AUTOSAR XML (schema 4-3-0)
standard types defined: boolean, float64, uint16, uint8, boolean_CompuMethod, boolean_DataConstr, float64_DataConstr, uint16_DataConstr, uint8_DataConstr
package /ComponentTypes
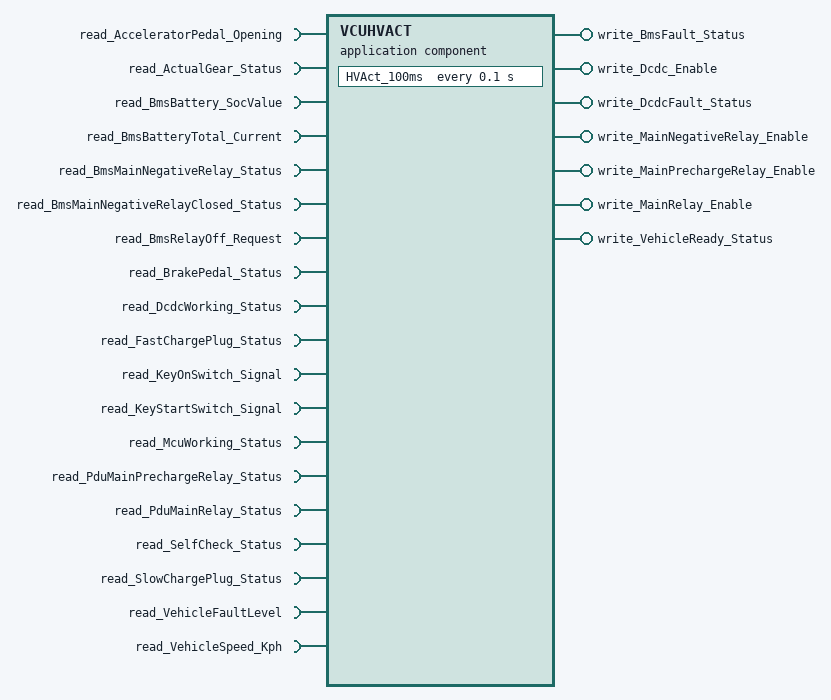
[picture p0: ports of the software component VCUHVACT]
  application sw component type VCUHVACT
    7 x provide port:
      write_BmsFault_Status: nonqueued-sender-com-spec{data-element=write_BmsFault_Status/unit8_t, init-value=0}, provided-interface=write_BmsFault_Status
      write_Dcdc_Enable: nonqueued-sender-com-spec{data-element=write_Dcdc_Enable/uint8_t, init-value=0}, provided-interface=write_Dcdc_Enable
      write_DcdcFault_Status: nonqueued-sender-com-spec{data-element=write_DcdcFault_Status/uint8_t, init-value=0}, provided-interface=write_DcdcFault_Status
      write_MainNegativeRelay_Enable: nonqueued-sender-com-spec{data-element=write_MainNegativeRelay_Enable/unit8_t, init-value=0}, provided-interface=write_MainNegativeRelay_Enable
      write_MainPrechargeRelay_Enable: nonqueued-sender-com-spec{data-element=write_MainPrechargeRelay_Enable/uint8_t, init-value=0}, provided-interface=write_MainPrechargeRelay_Enable
      write_MainRelay_Enable: nonqueued-sender-com-spec{data-element=write_MainRelay_Enable/uint8_t, init-value=0}, provided-interface=write_MainRelay_Enable
      write_VehicleReady_Status: nonqueued-sender-com-spec{data-element=write_VehicleReady_Status/uint8_t, init-value=0}, provided-interface=write_VehicleReady_Status
    19 x require port:
      read_AcceleratorPedal_Opening: nonqueued-receiver-com-spec{data-element=uint16_t, filter=data-filter-type=ALWAYS, init-value=0}, required-interface=read_AcceleratorPedal_Opening
      read_ActualGear_Status: nonqueued-receiver-com-spec{data-element=read_ActualGear_Status/uint8_t, filter=data-filter-type=ALWAYS, init-value=0}, required-interface=read_ActualGear_Status
      read_BmsBattery_SocValue: nonqueued-receiver-com-spec{data-element=read_BmsBattery_SocValue/float64, filter=data-filter-type=ALWAYS, init-value=0}, required-interface=read_BmsBattery_SocValue
      read_BmsBatteryTotal_Current: nonqueued-receiver-com-spec{data-element=read_BmsBatteryTotal_Current/float64, filter=data-filter-type=ALWAYS, init-value=0}, required-interface=read_BmsBatteryTotal_Current
      read_BmsMainNegativeRelay_Status: nonqueued-receiver-com-spec{data-element=read_BmsMainNegativeRelay_Status/bool, filter=data-filter-type=ALWAYS, init-value=0}, required-interface=read_BmsMainNegativeRelay_Status
      read_BmsMainNegativeRelayClosed_Status: nonqueued-receiver-com-spec{data-element=read_BmsMainNegativeRelayClosed_Status/uint8_t, filter=data-filter-type=ALWAYS, init-value=0}, required-interface=read_BmsMainNegativeRelayClosed_Status
      read_BmsRelayOff_Request: nonqueued-receiver-com-spec{data-element=read_BmsRelayOff_Request/uint8_t, filter=data-filter-type=ALWAYS, init-value=0}, required-interface=read_BmsRelayOff_Request
      read_BrakePedal_Status: nonqueued-receiver-com-spec{data-element=read_BrakePedal_Status/uint8_t, filter=data-filter-type=ALWAYS, init-value=0}, required-interface=read_BrakePedal_Status
      read_DcdcWorking_Status: nonqueued-receiver-com-spec{data-element=read_DcdcWorking_Status/uint8_t, filter=data-filter-type=ALWAYS, init-value=0}, required-interface=read_DcdcWorking_Status
      read_FastChargePlug_Status: nonqueued-receiver-com-spec{data-element=read_FastChargePlug_Status/bool, filter=data-filter-type=ALWAYS, init-value=0}, required-interface=read_FastChargePlug_Status
      read_KeyOnSwitch_Signal: nonqueued-receiver-com-spec{data-element=read_KeyOnSwitch_Signal/bool, filter=data-filter-type=ALWAYS, init-value=0}, required-interface=read_KeyOnSwitch_Signal
      read_KeyStartSwitch_Signal: nonqueued-receiver-com-spec{data-element=read_KeyStartSwitch_Signal/bool, filter=data-filter-type=ALWAYS, init-value=0}, required-interface=read_KeyStartSwitch_Signal
      read_McuWorking_Status: nonqueued-receiver-com-spec{data-element=read_McuWorking_Status/uint8_t, filter=data-filter-type=ALWAYS, init-value=0}, required-interface=read_McuWorking_Status
      read_PduMainPrechargeRelay_Status: nonqueued-receiver-com-spec{data-element=read_PduMainPrechargeRelay_Status/uint8_t, filter=data-filter-type=ALWAYS, init-value=0}, required-interface=read_PduMainPrechargeRelay_Status
      read_PduMainRelay_Status: nonqueued-receiver-com-spec{data-element=read_PduMainRelay_Status/uint8_t, filter=data-filter-type=ALWAYS, init-value=0}, required-interface=read_PduMainRelay_Status
      read_SelfCheck_Status: nonqueued-receiver-com-spec{data-element=read_SelfCheck_Status/bool, filter=data-filter-type=ALWAYS, init-value=0}, required-interface=read_SelfCheck_Status
      read_SlowChargePlug_Status: nonqueued-receiver-com-spec{data-element=read_SlowChargePlug_Status/bool, filter=data-filter-type=ALWAYS, init-value=0}, required-interface=read_SlowChargePlug_Status
      read_VehicleFaultLevel: nonqueued-receiver-com-spec{data-element=read_VehicleFaultLevel/uint8_t, filter=data-filter-type=ALWAYS, init-value=0}, required-interface=read_VehicleFaultLevel
      read_VehicleSpeed_Kph: nonqueued-receiver-com-spec{data-element=read_VehicleSpeed_Kph/float64, filter=data-filter-type=ALWAYS, init-value=0}, required-interface=read_VehicleSpeed_Kph
    behavior VCUHVACT_InternalBehavior
      timing event TMT_HVAct_100ms: start-on-event=HVAct_100ms, period=0.1
      runnable HVAct_100ms: minimum-start-interval=0.1
        data-receive-point-by-arguments:
          19 x access:
            REC_read_AcceleratorPedal_Opening_uint16_t: accessed-variable=read_AcceleratorPedal_Opening.uint16_t
            REC_read_ActualGear_Status_uint8_t: accessed-variable=read_ActualGear_Status.uint8_t
            REC_read_BmsBattery_SocValue_float64: accessed-variable=read_BmsBattery_SocValue.float64
            REC_read_BmsBatteryTotal_Current_float64: accessed-variable=read_BmsBatteryTotal_Current.float64
            REC_read_BmsMainNegativeRelay_Status_bool: accessed-variable=read_BmsMainNegativeRelay_Status.bool
            REC_read_BmsMainNegativeRelayClosed_Status_uint8_t: accessed-variable=read_BmsMainNegativeRelayClosed_Status.uint8_t
            REC_read_BmsRelayOff_Request_uint8_t: accessed-variable=read_BmsRelayOff_Request.uint8_t
            REC_read_BrakePedal_Status_uint8_t: accessed-variable=read_BrakePedal_Status.uint8_t
            REC_read_DcdcWorking_Status_uint8_t: accessed-variable=read_DcdcWorking_Status.uint8_t
            REC_read_FastChargePlug_Status_bool: accessed-variable=read_FastChargePlug_Status.bool
            REC_read_KeyOnSwitch_Signal_bool: accessed-variable=read_KeyOnSwitch_Signal.bool
            REC_read_KeyStartSwitch_Signal_bool: accessed-variable=read_KeyStartSwitch_Signal.bool
            REC_read_McuWorking_Status_uint8_t: accessed-variable=read_McuWorking_Status.uint8_t
            REC_read_PduMainPrechargeRelay_Status_uint8_t: accessed-variable=read_PduMainPrechargeRelay_Status.uint8_t
            REC_read_PduMainRelay_Status_uint8_t: accessed-variable=read_PduMainRelay_Status.uint8_t
            REC_read_SelfCheck_Status_bool: accessed-variable=read_SelfCheck_Status.bool
            REC_read_SlowChargePlug_Status_bool: accessed-variable=read_SlowChargePlug_Status.bool
            REC_read_VehicleFaultLevel_uint8_t: accessed-variable=read_VehicleFaultLevel.uint8_t
            REC_read_VehicleSpeed_Kph_float64: accessed-variable=read_VehicleSpeed_Kph.float64
        data-send-points:
          7 x access:
            SEND_write_BmsFault_Status_unit8_t: accessed-variable=write_BmsFault_Status.unit8_t
            SEND_write_Dcdc_Enable_uint8_t: accessed-variable=write_Dcdc_Enable.uint8_t
            SEND_write_DcdcFault_Status_uint8_t: accessed-variable=write_DcdcFault_Status.uint8_t
            SEND_write_MainNegativeRelay_Enable_unit8_t: accessed-variable=write_MainNegativeRelay_Enable.unit8_t
            SEND_write_MainPrechargeRelay_Enable_uint8_t: accessed-variable=write_MainPrechargeRelay_Enable.uint8_t
            SEND_write_MainRelay_Enable_uint8_t: accessed-variable=write_MainRelay_Enable.uint8_t
            SEND_write_VehicleReady_Status_uint8_t: accessed-variable=write_VehicleReady_Status.uint8_t
  swc implementation VCUHVACT_Implementation: behavior=VCUHVACT_InternalBehavior
    code-descriptors:
      code Default: artifact-descriptors=autosar-engineering-object={short-label=Default, category=SWSRC}
package /PortInterfaces
  26 x sender receiver interface:
    read_AcceleratorPedal_Opening: invalidation-policy{data-element=uint16_t, handle-invalid=DONT-INVALIDATE}
      data uint16_t: type=uint16
    read_ActualGear_Status: invalidation-policy{data-element=read_ActualGear_Status/uint8_t, handle-invalid=DONT-INVALIDATE}
      data uint8_t: type=uint8
    read_BmsBattery_SocValue: invalidation-policy{data-element=read_BmsBattery_SocValue/float64, handle-invalid=DONT-INVALIDATE}
      data float64: type=float64
    read_BmsBatteryTotal_Current: invalidation-policy{data-element=read_BmsBatteryTotal_Current/float64, handle-invalid=DONT-INVALIDATE}
      data float64: type=float64
    read_BmsMainNegativeRelay_Status: invalidation-policy{data-element=read_BmsMainNegativeRelay_Status/bool, handle-invalid=DONT-INVALIDATE}
      data bool: type=boolean
    read_BmsMainNegativeRelayClosed_Status: invalidation-policy{data-element=read_BmsMainNegativeRelayClosed_Status/uint8_t, handle-invalid=DONT-INVALIDATE}
      data uint8_t: type=uint8
    read_BmsRelayOff_Request: invalidation-policy{data-element=read_BmsRelayOff_Request/uint8_t, handle-invalid=DONT-INVALIDATE}
      data uint8_t: type=uint8
    read_BrakePedal_Status: invalidation-policy{data-element=read_BrakePedal_Status/uint8_t, handle-invalid=DONT-INVALIDATE}
      data uint8_t: type=uint8
    read_DcdcWorking_Status: invalidation-policy{data-element=read_DcdcWorking_Status/uint8_t, handle-invalid=DONT-INVALIDATE}
      data uint8_t: type=uint8
    read_FastChargePlug_Status: invalidation-policy{data-element=read_FastChargePlug_Status/bool, handle-invalid=DONT-INVALIDATE}
      data bool: type=boolean
    read_KeyOnSwitch_Signal: invalidation-policy{data-element=read_KeyOnSwitch_Signal/bool, handle-invalid=DONT-INVALIDATE}
      data bool: type=boolean
    read_KeyStartSwitch_Signal: invalidation-policy{data-element=read_KeyStartSwitch_Signal/bool, handle-invalid=DONT-INVALIDATE}
      data bool: type=boolean
    read_McuWorking_Status: invalidation-policy{data-element=read_McuWorking_Status/uint8_t, handle-invalid=DONT-INVALIDATE}
      data uint8_t: type=uint8
    read_PduMainPrechargeRelay_Status: invalidation-policy{data-element=read_PduMainPrechargeRelay_Status/uint8_t, handle-invalid=DONT-INVALIDATE}
      data uint8_t: type=uint8
    read_PduMainRelay_Status: invalidation-policy{data-element=read_PduMainRelay_Status/uint8_t, handle-invalid=DONT-INVALIDATE}
      data uint8_t: type=uint8
    read_SelfCheck_Status: invalidation-policy{data-element=read_SelfCheck_Status/bool, handle-invalid=DONT-INVALIDATE}
      data bool: type=boolean
    read_SlowChargePlug_Status: invalidation-policy{data-element=read_SlowChargePlug_Status/bool, handle-invalid=DONT-INVALIDATE}
      data bool: type=boolean
    read_VehicleFaultLevel: invalidation-policy{data-element=read_VehicleFaultLevel/uint8_t, handle-invalid=DONT-INVALIDATE}
      data uint8_t: type=uint8
    read_VehicleSpeed_Kph: invalidation-policy{data-element=read_VehicleSpeed_Kph/float64, handle-invalid=DONT-INVALIDATE}
      data float64: type=float64
    write_BmsFault_Status: invalidation-policy{data-element=write_BmsFault_Status/unit8_t, handle-invalid=DONT-INVALIDATE}
      data unit8_t: type=uint8
    write_Dcdc_Enable: invalidation-policy{data-element=write_Dcdc_Enable/uint8_t, handle-invalid=DONT-INVALIDATE}
      data uint8_t: type=uint8
    write_DcdcFault_Status: invalidation-policy{data-element=write_DcdcFault_Status/uint8_t, handle-invalid=DONT-INVALIDATE}
      data uint8_t: type=uint8
    write_MainNegativeRelay_Enable: invalidation-policy{data-element=write_MainNegativeRelay_Enable/unit8_t, handle-invalid=DONT-INVALIDATE}
      data unit8_t: type=uint8
    write_MainPrechargeRelay_Enable: invalidation-policy{data-element=write_MainPrechargeRelay_Enable/uint8_t, handle-invalid=DONT-INVALIDATE}
      data uint8_t: type=uint8
    write_MainRelay_Enable: invalidation-policy{data-element=write_MainRelay_Enable/uint8_t, handle-invalid=DONT-INVALIDATE}
      data uint8_t: type=uint8
    write_VehicleReady_Status: invalidation-policy{data-element=write_VehicleReady_Status/uint8_t, handle-invalid=DONT-INVALIDATE}
      data uint8_t: type=uint8
